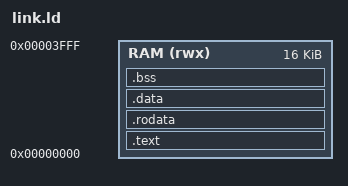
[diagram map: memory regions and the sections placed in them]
/* Single RAM region: code, data, bss and stack share the SoC RAM. */
OUTPUT_ARCH("riscv")
ENTRY(_start)

MEMORY
{
    RAM (rwx) : ORIGIN = 0x00000000, LENGTH = 16K
}

SECTIONS
{
    .text : {
        KEEP(*(.text.init))
        *(.text .text.*)
    } > RAM

    .rodata : { *(.rodata .rodata.* .srodata .srodata.*) } > RAM

    .data : {
        . = ALIGN(4);
        *(.data .data.* .sdata .sdata.*)
    } > RAM

    .bss (NOLOAD) : {
        . = ALIGN(4);
        __bss_start = .;
        *(.bss .bss.* .sbss .sbss.* COMMON)
        . = ALIGN(4);
        __bss_end = .;
    } > RAM

    __stack_top = ORIGIN(RAM) + LENGTH(RAM);
    __global_pointer$ = __bss_start;
}
